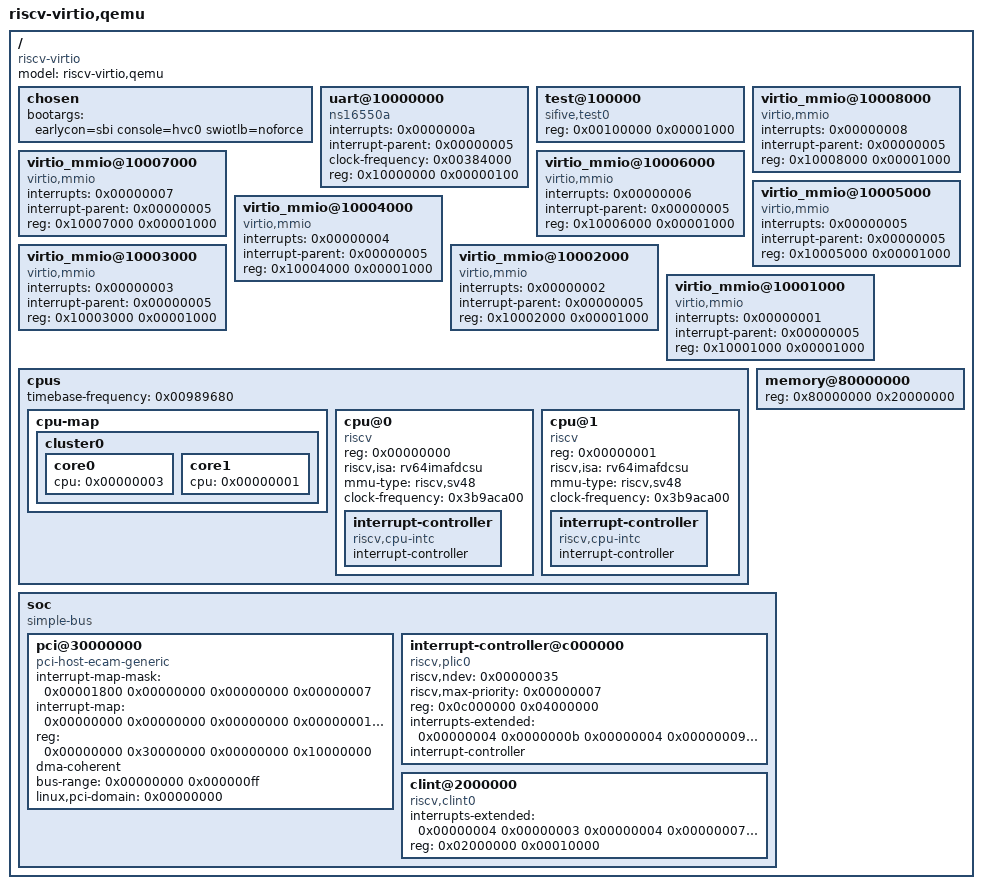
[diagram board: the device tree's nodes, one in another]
/dts-v1/;
/ {
  #address-cells = <0x00000001>;
  #size-cells = <0x00000001>;
  compatible = "riscv-virtio";
  model = "riscv-virtio,qemu";
  chosen {
    bootargs = "earlycon=sbi console=hvc0 swiotlb=noforce";
  };
  uart@10000000 {
    interrupts = <0x0000000a>;
    interrupt-parent = <0x00000005>;
    clock-frequency = <0x00384000>;
    reg = <0x10000000 0x00000100>;
    compatible = "ns16550a";
  };
  test@100000 {
    reg = <0x00100000 0x00001000>;
    compatible = "sifive,test0";
  };
  virtio_mmio@10008000 {
    interrupts = <0x00000008>;
    interrupt-parent = <0x00000005>;
    reg = <0x10008000 0x00001000>;
    compatible = "virtio,mmio";
  };
  virtio_mmio@10007000 {
    interrupts = <0x00000007>;
    interrupt-parent = <0x00000005>;
    reg = <0x10007000 0x00001000>;
    compatible = "virtio,mmio";
  };
  virtio_mmio@10006000 {
    interrupts = <0x00000006>;
    interrupt-parent = <0x00000005>;
    reg = <0x10006000 0x00001000>;
    compatible = "virtio,mmio";
  };
  virtio_mmio@10005000 {
    interrupts = <0x00000005>;
    interrupt-parent = <0x00000005>;
    reg = <0x10005000 0x00001000>;
    compatible = "virtio,mmio";
  };
  virtio_mmio@10004000 {
    interrupts = <0x00000004>;
    interrupt-parent = <0x00000005>;
    reg = <0x10004000 0x00001000>;
    compatible = "virtio,mmio";
  };
  virtio_mmio@10003000 {
    interrupts = <0x00000003>;
    interrupt-parent = <0x00000005>;
    reg = <0x10003000 0x00001000>;
    compatible = "virtio,mmio";
  };
  virtio_mmio@10002000 {
    interrupts = <0x00000002>;
    interrupt-parent = <0x00000005>;
    reg = <0x10002000 0x00001000>;
    compatible = "virtio,mmio";
  };
  virtio_mmio@10001000 {
    interrupts = <0x00000001>;
    interrupt-parent = <0x00000005>;
    reg = <0x10001000 0x00001000>;
    compatible = "virtio,mmio";
  };
  cpus {
    #address-cells = <0x00000001>;
    #size-cells = <0x00000000>;
    timebase-frequency = <0x00989680>;
    cpu-map {
      cluster0 {
        core0 {
          cpu = <0x00000003>;
        };
        core1 {
          cpu = <0x00000001>;
        };
      };
    };
    cpu@0 {
      linux,phandle = <0x00000003>;
      phandle = <0x00000003>;
      device_type = "cpu";
      reg = <0x00000000>;
      status = "okay";
      compatible = "riscv";
      riscv,isa = "rv64imafdcsu";
      mmu-type = "riscv,sv48";
      clock-frequency = <0x3b9aca00>;
      interrupt-controller {
        #interrupt-cells = <0x00000001>;
        interrupt-controller;
        compatible = "riscv,cpu-intc";
        linux,phandle = <0x00000004>;
        phandle = <0x00000004>;
      };
    };
    cpu@1 {
      linux,phandle = <0x00000001>;
      phandle = <0x00000001>;
      device_type = "cpu";
      reg = <0x00000001>;
      status = "okay";
      compatible = "riscv";
      riscv,isa = "rv64imafdcsu";
      mmu-type = "riscv,sv48";
      clock-frequency = <0x3b9aca00>;
      interrupt-controller {
        #interrupt-cells = <0x00000001>;
        interrupt-controller;
        compatible = "riscv,cpu-intc";
        linux,phandle = <0x00000002>;
        phandle = <0x00000002>;
      };
    };
  };
  memory@80000000 {
    device_type = "memory";
    reg = <0x80000000 0x20000000>;
  };
  soc {
    #address-cells = <0x00000001>;
    #size-cells = <0x00000001>;
    compatible = "simple-bus";
    ranges;
    pci@30000000 {
      interrupt-map-mask = <0x00001800 0x00000000 0x00000000 0x00000007>;
      interrupt-map = <0x00000000 0x00000000 0x00000000 0x00000001 0x00000005 0x00000020 0x00000000 0x00000000 0x00000000 0x00000002 0x00000005 0x00000021 0x00000000 0x00000000 0x00000000 0x00000003 0x00000005 0x00000022 0x00000000 0x00000000 0x00000000 0x00000004 0x00000005 0x00000023 0x00000800 0x00000000 0x00000000 0x00000001 0x00000005 0x00000021 0x00000800 0x00000000 0x00000000 0x00000002 0x00000005 0x00000022 0x00000800 0x00000000 0x00000000 0x00000003 0x00000005 0x00000023 0x00000800 0x00000000 0x00000000 0x00000004 0x00000005 0x00000020 0x00001000 0x00000000 0x00000000 0x00000001 0x00000005 0x00000022 0x00001000 0x00000000 0x00000000 0x00000002 0x00000005 0x00000023 0x00001000 0x00000000 0x00000000 0x00000003 0x00000005 0x00000020 0x00001000 0x00000000 0x00000000 0x00000004 0x00000005 0x00000021 0x00001800 0x00000000 0x00000000 0x00000001 0x00000005 0x00000023 0x00001800 0x00000000 0x00000000 0x00000002 0x00000005 0x00000020 0x00001800 0x00000000 0x00000000 0x00000003 0x00000005 0x00000021 0x00001800 0x00000000 0x00000000 0x00000004 0x00000005 0x00000022>;
      ranges = <0x01000000 0x00000000 0x00000000 0x00000000 0x03000000 0x00000000 0x00010000 0x02000000 0x00000000 0x40000000 0x00000000 0x40000000 0x00000000 0x40000000>;
      reg = <0x00000000 0x30000000 0x00000000 0x10000000>;
      dma-coherent;
      bus-range = <0x00000000 0x000000ff>;
      linux,pci-domain = <0x00000000>;
      device_type = "pci";
      compatible = "pci-host-ecam-generic";
      #size-cells = <0x00000002>;
      #interrupt-cells = <0x00000001>;
      #address-cells = <0x00000003>;
    };
    interrupt-controller@c000000 {
      linux,phandle = <0x00000005>;
      phandle = <0x00000005>;
      riscv,ndev = <0x00000035>;
      riscv,max-priority = <0x00000007>;
      reg-names = "control";
      reg = <0x0c000000 0x04000000>;
      interrupts-extended = <0x00000004 0x0000000b 0x00000004 0x00000009 0x00000002 0x0000000b 0x00000002 0x00000009>;
      interrupt-controller;
      compatible = "riscv,plic0";
      #interrupt-cells = <0x00000001>;
      #address-cells = <0x00000000>;
    };
    clint@2000000 {
      interrupts-extended = <0x00000004 0x00000003 0x00000004 0x00000007 0x00000002 0x00000003 0x00000002 0x00000007>;
      reg = <0x02000000 0x00010000>;
      compatible = "riscv,clint0";
    };
  };
};

